AUTOSAR XML (schema 4-0-3)
standard types defined: Boolean, UInt8
package /AUTOSAR_Platform/DataConstrs
  range DC_Boolean: raw 0..1
package /PATAC/Facility/DataTypes/Implementation
  compu method COMPU_Boolean: 0=FALSE, 1=TRUE
  unit NoUnit: factor-si-to-unit=1, offset-si-to-unit=0
package /PATAC/MSM/ComponentTypes
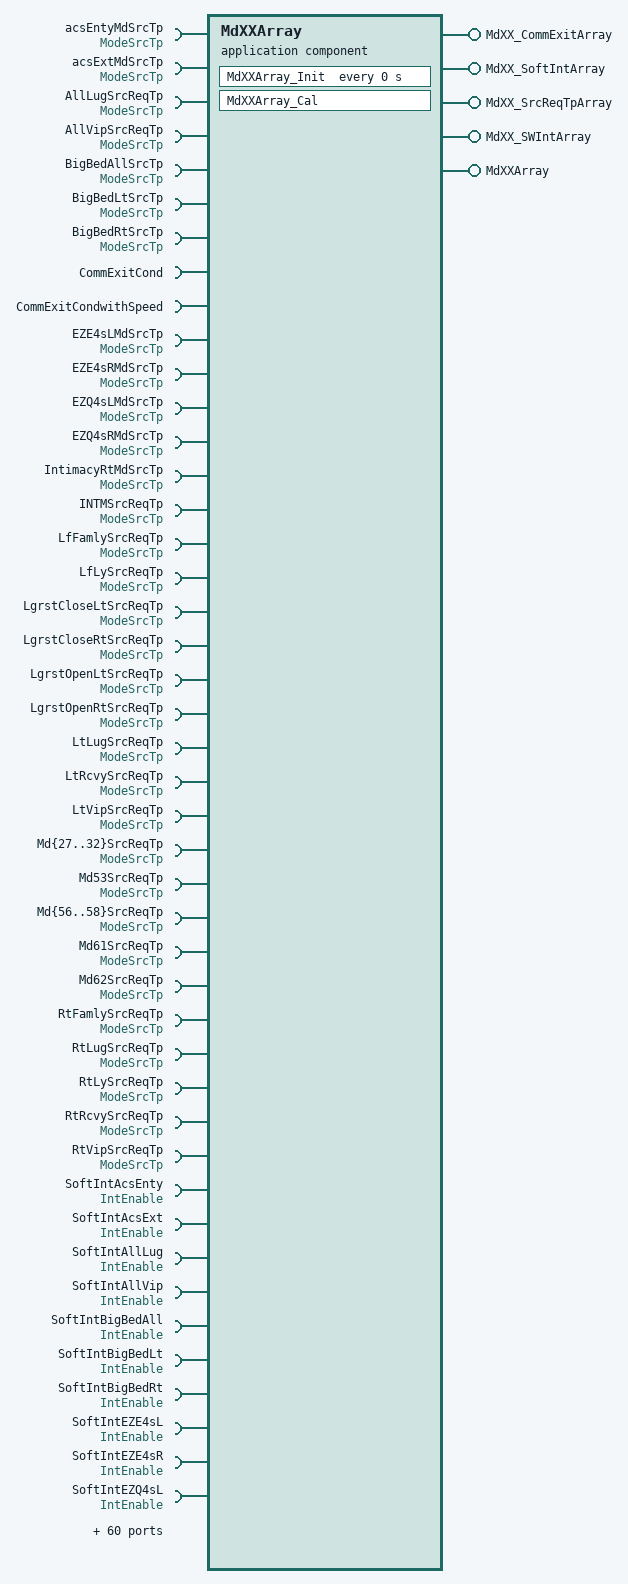
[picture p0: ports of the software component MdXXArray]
  application sw component type MdXXArray
    5 x provide port:
      MdXX_CommExitArray: nonqueued-sender-com-spec=data-element=MdXX_CommExitArray/Val, provided-interface=MdXX_CommExitArray
      MdXX_SoftIntArray: nonqueued-sender-com-spec{data-element=MdXX_SoftIntArray/Val, init-value=32 x 0}, provided-interface=MdXX_SoftIntArray
      MdXX_SrcReqTpArray: nonqueued-sender-com-spec{data-element=MdXX_SrcReqTpArray/Val, init-value=32 x 0}, provided-interface=MdXX_SrcReqTpArray
      MdXX_SWIntArray: nonqueued-sender-com-spec{data-element=MdXX_SWIntArray/Val, init-value=32 x 0}, provided-interface=MdXX_SWIntArray
      MdXXArray: server-com-spec{operation=Cal, queue-length=1}, provided-interface=MdXXArray
    125 x require port:
      acsEntyMdSrcTp: nonqueued-receiver-com-spec{data-element=ModeSrcTp/Val, filter=data-filter-type=ALWAYS, init-value=0}, required-interface=ModeSrcTp
      acsExtMdSrcTp: nonqueued-receiver-com-spec{data-element=ModeSrcTp/Val, filter=data-filter-type=ALWAYS, init-value=0}, required-interface=ModeSrcTp
      AllLugSrcReqTp: nonqueued-receiver-com-spec{data-element=ModeSrcTp/Val, filter=data-filter-type=ALWAYS, init-value=0}, required-interface=ModeSrcTp
      AllVipSrcReqTp: nonqueued-receiver-com-spec{data-element=ModeSrcTp/Val, filter=data-filter-type=ALWAYS, init-value=0}, required-interface=ModeSrcTp
      BigBedAllSrcTp: nonqueued-receiver-com-spec{data-element=ModeSrcTp/Val, filter=data-filter-type=ALWAYS, init-value=0}, required-interface=ModeSrcTp
      BigBedLtSrcTp: nonqueued-receiver-com-spec{data-element=ModeSrcTp/Val, filter=data-filter-type=ALWAYS, init-value=0}, required-interface=ModeSrcTp
      BigBedRtSrcTp: nonqueued-receiver-com-spec{data-element=ModeSrcTp/Val, filter=data-filter-type=ALWAYS, init-value=0}, required-interface=ModeSrcTp
      CommExitCond: nonqueued-receiver-com-spec{data-element=CommExitCond/Val, filter=data-filter-type=ALWAYS, init-value=0}, required-interface=CommExitCond
      CommExitCondwithSpeed: nonqueued-receiver-com-spec{data-element=CommExitCondwithSpeed/Val, filter=data-filter-type=ALWAYS, init-value=0}, required-interface=CommExitCondwithSpeed
      EZE4sLMdSrcTp: nonqueued-receiver-com-spec{data-element=ModeSrcTp/Val, filter=data-filter-type=ALWAYS, init-value=0}, required-interface=ModeSrcTp
      EZE4sRMdSrcTp: nonqueued-receiver-com-spec{data-element=ModeSrcTp/Val, filter=data-filter-type=ALWAYS, init-value=0}, required-interface=ModeSrcTp
      EZQ4sLMdSrcTp: nonqueued-receiver-com-spec{data-element=ModeSrcTp/Val, filter=data-filter-type=ALWAYS, init-value=0}, required-interface=ModeSrcTp
      EZQ4sRMdSrcTp: nonqueued-receiver-com-spec{data-element=ModeSrcTp/Val, filter=data-filter-type=ALWAYS, init-value=0}, required-interface=ModeSrcTp
      IntimacyRtMdSrcTp: nonqueued-receiver-com-spec{data-element=ModeSrcTp/Val, filter=data-filter-type=ALWAYS, init-value=0}, required-interface=ModeSrcTp
      INTMSrcReqTp: nonqueued-receiver-com-spec{data-element=ModeSrcTp/Val, filter=data-filter-type=ALWAYS, init-value=0}, required-interface=ModeSrcTp
      LfFamlySrcReqTp: nonqueued-receiver-com-spec{data-element=ModeSrcTp/Val, filter=data-filter-type=ALWAYS, init-value=0}, required-interface=ModeSrcTp
      LfLySrcReqTp: nonqueued-receiver-com-spec{data-element=ModeSrcTp/Val, filter=data-filter-type=ALWAYS, init-value=0}, required-interface=ModeSrcTp
      LgrstCloseLtSrcReqTp: nonqueued-receiver-com-spec{data-element=ModeSrcTp/Val, filter=data-filter-type=ALWAYS, init-value=0}, required-interface=ModeSrcTp
      LgrstCloseRtSrcReqTp: nonqueued-receiver-com-spec{data-element=ModeSrcTp/Val, filter=data-filter-type=ALWAYS, init-value=0}, required-interface=ModeSrcTp
      LgrstOpenLtSrcReqTp: nonqueued-receiver-com-spec{data-element=ModeSrcTp/Val, filter=data-filter-type=ALWAYS, init-value=0}, required-interface=ModeSrcTp
      LgrstOpenRtSrcReqTp: nonqueued-receiver-com-spec{data-element=ModeSrcTp/Val, filter=data-filter-type=ALWAYS, init-value=0}, required-interface=ModeSrcTp
      LtLugSrcReqTp: nonqueued-receiver-com-spec{data-element=ModeSrcTp/Val, filter=data-filter-type=ALWAYS, init-value=0}, required-interface=ModeSrcTp
      LtRcvySrcReqTp: nonqueued-receiver-com-spec{data-element=ModeSrcTp/Val, filter=data-filter-type=ALWAYS, init-value=0}, required-interface=ModeSrcTp
      LtVipSrcReqTp: nonqueued-receiver-com-spec{data-element=ModeSrcTp/Val, filter=data-filter-type=ALWAYS, init-value=0}, required-interface=ModeSrcTp
      Md{27..32}SrcReqTp: nonqueued-receiver-com-spec{data-element=ModeSrcTp/Val, filter=data-filter-type=ALWAYS, init-value=0}, required-interface=ModeSrcTp
      Md53SrcReqTp: nonqueued-receiver-com-spec{data-element=ModeSrcTp/Val, filter=data-filter-type=ALWAYS, init-value=0}, required-interface=ModeSrcTp
      Md{56..58}SrcReqTp: nonqueued-receiver-com-spec{data-element=ModeSrcTp/Val, filter=data-filter-type=ALWAYS, init-value=0}, required-interface=ModeSrcTp
      Md61SrcReqTp: nonqueued-receiver-com-spec{data-element=ModeSrcTp/Val, filter=data-filter-type=ALWAYS, init-value=0}, required-interface=ModeSrcTp
      Md62SrcReqTp: nonqueued-receiver-com-spec{data-element=ModeSrcTp/Val, filter=data-filter-type=ALWAYS, init-value=0}, required-interface=ModeSrcTp
      RtFamlySrcReqTp: nonqueued-receiver-com-spec{data-element=ModeSrcTp/Val, filter=data-filter-type=ALWAYS, init-value=0}, required-interface=ModeSrcTp
      RtLugSrcReqTp: nonqueued-receiver-com-spec{data-element=ModeSrcTp/Val, filter=data-filter-type=ALWAYS, init-value=0}, required-interface=ModeSrcTp
      RtLySrcReqTp: nonqueued-receiver-com-spec{data-element=ModeSrcTp/Val, filter=data-filter-type=ALWAYS, init-value=0}, required-interface=ModeSrcTp
      RtRcvySrcReqTp: nonqueued-receiver-com-spec{data-element=ModeSrcTp/Val, filter=data-filter-type=ALWAYS, init-value=0}, required-interface=ModeSrcTp
      RtVipSrcReqTp: nonqueued-receiver-com-spec{data-element=ModeSrcTp/Val, filter=data-filter-type=ALWAYS, init-value=0}, required-interface=ModeSrcTp
      SoftIntAcsEnty: nonqueued-receiver-com-spec{data-element=IntEnable/Val, filter=data-filter-type=ALWAYS, init-value=0}, required-interface=IntEnable
      SoftIntAcsExt: nonqueued-receiver-com-spec{data-element=IntEnable/Val, filter=data-filter-type=ALWAYS, init-value=0}, required-interface=IntEnable
      SoftIntAllLug: nonqueued-receiver-com-spec{data-element=IntEnable/Val, filter=data-filter-type=ALWAYS, init-value=0}, required-interface=IntEnable
      SoftIntAllVip: nonqueued-receiver-com-spec{data-element=IntEnable/Val, filter=data-filter-type=ALWAYS, init-value=0}, required-interface=IntEnable
      SoftIntBigBedAll: nonqueued-receiver-com-spec{data-element=IntEnable/Val, filter=data-filter-type=ALWAYS, init-value=0}, required-interface=IntEnable
      SoftIntBigBedLt: nonqueued-receiver-com-spec{data-element=IntEnable/Val, filter=data-filter-type=ALWAYS, init-value=0}, required-interface=IntEnable
      SoftIntBigBedRt: nonqueued-receiver-com-spec{data-element=IntEnable/Val, filter=data-filter-type=ALWAYS, init-value=0}, required-interface=IntEnable
      SoftIntEZE4sL: nonqueued-receiver-com-spec{data-element=IntEnable/Val, filter=data-filter-type=ALWAYS, init-value=0}, required-interface=IntEnable
      SoftIntEZE4sR: nonqueued-receiver-com-spec{data-element=IntEnable/Val, filter=data-filter-type=ALWAYS, init-value=0}, required-interface=IntEnable
      SoftIntEZQ4sL: nonqueued-receiver-com-spec{data-element=IntEnable/Val, filter=data-filter-type=ALWAYS, init-value=0}, required-interface=IntEnable
      SoftIntEZQ4sR: nonqueued-receiver-com-spec{data-element=IntEnable/Val, filter=data-filter-type=ALWAYS, init-value=0}, required-interface=IntEnable
      SoftIntIntimacyRt: nonqueued-receiver-com-spec{data-element=IntEnable/Val, filter=data-filter-type=ALWAYS, init-value=0}, required-interface=IntEnable
      SoftIntINTM: nonqueued-receiver-com-spec{data-element=IntEnable/Val, filter=data-filter-type=ALWAYS, init-value=0}, required-interface=IntEnable
      SoftIntLfFamly: nonqueued-receiver-com-spec{data-element=IntEnable/Val, filter=data-filter-type=ALWAYS, init-value=0}, required-interface=IntEnable
      SoftIntLfLug: nonqueued-receiver-com-spec{data-element=IntEnable/Val, filter=data-filter-type=ALWAYS, init-value=0}, required-interface=IntEnable
      SoftIntLfLy: nonqueued-receiver-com-spec{data-element=IntEnable/Val, filter=data-filter-type=ALWAYS, init-value=0}, required-interface=IntEnable
      SoftIntLfRcvy: nonqueued-receiver-com-spec{data-element=IntEnable/Val, filter=data-filter-type=ALWAYS, init-value=0}, required-interface=IntEnable
      SoftIntLfVip: nonqueued-receiver-com-spec{data-element=IntEnable/Val, filter=data-filter-type=ALWAYS, init-value=0}, required-interface=IntEnable
      SoftIntLgrstCloseLt: nonqueued-receiver-com-spec{data-element=IntEnable/Val, filter=data-filter-type=ALWAYS, init-value=0}, required-interface=IntEnable
      SoftIntLgrstCloseRt: nonqueued-receiver-com-spec{data-element=IntEnable/Val, filter=data-filter-type=ALWAYS, init-value=0}, required-interface=IntEnable
      SoftIntLgrstOpenLt: nonqueued-receiver-com-spec{data-element=IntEnable/Val, filter=data-filter-type=ALWAYS, init-value=0}, required-interface=IntEnable
      SoftIntLgrstOpenRt: nonqueued-receiver-com-spec{data-element=IntEnable/Val, filter=data-filter-type=ALWAYS, init-value=0}, required-interface=IntEnable
      SoftIntMd{27..32}: nonqueued-receiver-com-spec{data-element=IntEnable/Val, filter=data-filter-type=ALWAYS, init-value=0}, required-interface=IntEnable
      SoftIntMd53: nonqueued-receiver-com-spec{data-element=IntEnable/Val, filter=data-filter-type=ALWAYS, init-value=0}, required-interface=IntEnable
      SoftIntMd{56..58}: nonqueued-receiver-com-spec{data-element=IntEnable/Val, filter=data-filter-type=ALWAYS, init-value=0}, required-interface=IntEnable
      SoftIntMd61: nonqueued-receiver-com-spec{data-element=IntEnable/Val, filter=data-filter-type=ALWAYS, init-value=0}, required-interface=IntEnable
      SoftIntMd62: nonqueued-receiver-com-spec{data-element=IntEnable/Val, filter=data-filter-type=ALWAYS, init-value=0}, required-interface=IntEnable
      SoftIntRtFamly: nonqueued-receiver-com-spec{data-element=IntEnable/Val, filter=data-filter-type=ALWAYS, init-value=0}, required-interface=IntEnable
      SoftIntRtLug: nonqueued-receiver-com-spec{data-element=IntEnable/Val, filter=data-filter-type=ALWAYS, init-value=0}, required-interface=IntEnable
      SoftIntRtLy: nonqueued-receiver-com-spec{data-element=IntEnable/Val, filter=data-filter-type=ALWAYS, init-value=0}, required-interface=IntEnable
      SoftIntRtRcvy: nonqueued-receiver-com-spec{data-element=IntEnable/Val, filter=data-filter-type=ALWAYS, init-value=0}, required-interface=IntEnable
      SoftIntRtVip: nonqueued-receiver-com-spec{data-element=IntEnable/Val, filter=data-filter-type=ALWAYS, init-value=0}, required-interface=IntEnable
      SoftIntWelcomeBkwd: nonqueued-receiver-com-spec{data-element=IntEnable/Val, filter=data-filter-type=ALWAYS, init-value=0}, required-interface=IntEnable
      SoftIntWelcomeFwd: nonqueued-receiver-com-spec{data-element=IntEnable/Val, filter=data-filter-type=ALWAYS, init-value=0}, required-interface=IntEnable
      SwIntAcsEnty: nonqueued-receiver-com-spec{data-element=IntEnable/Val, filter=data-filter-type=ALWAYS, init-value=0}, required-interface=IntEnable
      SwIntAcsExt: nonqueued-receiver-com-spec{data-element=IntEnable/Val, filter=data-filter-type=ALWAYS, init-value=0}, required-interface=IntEnable
      SwIntAllLug: nonqueued-receiver-com-spec{data-element=IntEnable/Val, filter=data-filter-type=ALWAYS, init-value=0}, required-interface=IntEnable
      SwIntAllVip: nonqueued-receiver-com-spec{data-element=IntEnable/Val, filter=data-filter-type=ALWAYS, init-value=0}, required-interface=IntEnable
      SwIntBigBedAll: nonqueued-receiver-com-spec{data-element=IntEnable/Val, filter=data-filter-type=ALWAYS, init-value=0}, required-interface=IntEnable
      SwIntBigBedLt: nonqueued-receiver-com-spec{data-element=IntEnable/Val, filter=data-filter-type=ALWAYS, init-value=0}, required-interface=IntEnable
      SwIntBigBedRt: nonqueued-receiver-com-spec{data-element=IntEnable/Val, filter=data-filter-type=ALWAYS, init-value=0}, required-interface=IntEnable
      SwIntEZE4sL: nonqueued-receiver-com-spec{data-element=IntEnable/Val, filter=data-filter-type=ALWAYS, init-value=0}, required-interface=IntEnable
      SwIntEZE4sR: nonqueued-receiver-com-spec{data-element=IntEnable/Val, filter=data-filter-type=ALWAYS, init-value=0}, required-interface=IntEnable
      SwIntEZQ4sL: nonqueued-receiver-com-spec{data-element=IntEnable/Val, filter=data-filter-type=ALWAYS, init-value=0}, required-interface=IntEnable
      SwIntEZQ4sR: nonqueued-receiver-com-spec{data-element=IntEnable/Val, filter=data-filter-type=ALWAYS, init-value=0}, required-interface=IntEnable
      SwIntIntimacyRt: nonqueued-receiver-com-spec{data-element=IntEnable/Val, filter=data-filter-type=ALWAYS, init-value=0}, required-interface=IntEnable
      SwIntINTM: nonqueued-receiver-com-spec{data-element=IntEnable/Val, filter=data-filter-type=ALWAYS, init-value=0}, required-interface=IntEnable
      SwIntLfFamly: nonqueued-receiver-com-spec{data-element=IntEnable/Val, filter=data-filter-type=ALWAYS, init-value=0}, required-interface=IntEnable
      SwIntLfLug: nonqueued-receiver-com-spec{data-element=IntEnable/Val, filter=data-filter-type=ALWAYS, init-value=0}, required-interface=IntEnable
      SwIntLfLy: nonqueued-receiver-com-spec{data-element=IntEnable/Val, filter=data-filter-type=ALWAYS, init-value=0}, required-interface=IntEnable
      SwIntLfRcvy: nonqueued-receiver-com-spec{data-element=IntEnable/Val, filter=data-filter-type=ALWAYS, init-value=0}, required-interface=IntEnable
      SwIntLfVip: nonqueued-receiver-com-spec{data-element=IntEnable/Val, filter=data-filter-type=ALWAYS, init-value=0}, required-interface=IntEnable
      SwIntLgrstCloseLt: nonqueued-receiver-com-spec{data-element=IntEnable/Val, filter=data-filter-type=ALWAYS, init-value=0}, required-interface=IntEnable
      SwIntLgrstCloseRt: nonqueued-receiver-com-spec{data-element=IntEnable/Val, filter=data-filter-type=ALWAYS, init-value=0}, required-interface=IntEnable
      SwIntLgrstOpenLt: nonqueued-receiver-com-spec{data-element=IntEnable/Val, filter=data-filter-type=ALWAYS, init-value=0}, required-interface=IntEnable
      SwIntLgrstOpenRt: nonqueued-receiver-com-spec{data-element=IntEnable/Val, filter=data-filter-type=ALWAYS, init-value=0}, required-interface=IntEnable
      SwIntMd{27..32}: nonqueued-receiver-com-spec{data-element=IntEnable/Val, filter=data-filter-type=ALWAYS, init-value=0}, required-interface=IntEnable
      SwIntMd53: nonqueued-receiver-com-spec{data-element=IntEnable/Val, filter=data-filter-type=ALWAYS, init-value=0}, required-interface=IntEnable
      SwIntMd{56..58}: nonqueued-receiver-com-spec{data-element=IntEnable/Val, filter=data-filter-type=ALWAYS, init-value=0}, required-interface=IntEnable
      SwIntMd61: nonqueued-receiver-com-spec{data-element=IntEnable/Val, filter=data-filter-type=ALWAYS, init-value=0}, required-interface=IntEnable
      SwIntMd62: nonqueued-receiver-com-spec{data-element=IntEnable/Val, filter=data-filter-type=ALWAYS, init-value=0}, required-interface=IntEnable
      SwIntRtFamly: nonqueued-receiver-com-spec{data-element=IntEnable/Val, filter=data-filter-type=ALWAYS, init-value=0}, required-interface=IntEnable
      SwIntRtLug: nonqueued-receiver-com-spec{data-element=IntEnable/Val, filter=data-filter-type=ALWAYS, init-value=0}, required-interface=IntEnable
      SwIntRtLy: nonqueued-receiver-com-spec{data-element=IntEnable/Val, filter=data-filter-type=ALWAYS, init-value=0}, required-interface=IntEnable
      SwIntRtRcvy: nonqueued-receiver-com-spec{data-element=IntEnable/Val, filter=data-filter-type=ALWAYS, init-value=0}, required-interface=IntEnable
      SwIntRtVip: nonqueued-receiver-com-spec{data-element=IntEnable/Val, filter=data-filter-type=ALWAYS, init-value=0}, required-interface=IntEnable
      SwIntWelcomeBkwd: nonqueued-receiver-com-spec{data-element=IntEnable/Val, filter=data-filter-type=ALWAYS, init-value=0}, required-interface=IntEnable
      SwIntWelcomeFwd: nonqueued-receiver-com-spec{data-element=IntEnable/Val, filter=data-filter-type=ALWAYS, init-value=0}, required-interface=IntEnable
      WelcomeBkwdMdSrcTp: nonqueued-receiver-com-spec{data-element=ModeSrcTp/Val, filter=data-filter-type=ALWAYS, init-value=0}, required-interface=ModeSrcTp
      WelcomeFwdMdSrcTp: nonqueued-receiver-com-spec{data-element=ModeSrcTp/Val, filter=data-filter-type=ALWAYS, init-value=0}, required-interface=ModeSrcTp
    behavior MdXXArray_InternalBehavior
      operation invoked event OIT_MdXXArray_Cal_MdXXArray_Cal: start-on-event=MdXXArray_Cal, operation=MdXXArray.Cal
      timing event MdXXArray_InitEvent: start-on-event=MdXXArray_Init, period=0
      runnable MdXXArray_Cal
        data-receive-point-by-arguments:
          125 x access:
            REC_acsEntyMdSrcTp_Val: accessed-variable=acsEntyMdSrcTp.Val
            REC_acsExtMdSrcTp_Val: accessed-variable=acsExtMdSrcTp.Val
            REC_AllLugSrcReqTp_Val: accessed-variable=AllLugSrcReqTp.Val
            REC_AllVipSrcReqTp_Val: accessed-variable=AllVipSrcReqTp.Val
            REC_BigBedAllSrcTp_Val: accessed-variable=BigBedAllSrcTp.Val
            REC_BigBedLtSrcTp_Val: accessed-variable=BigBedLtSrcTp.Val
            REC_BigBedRtSrcTp_Val: accessed-variable=BigBedRtSrcTp.Val
            REC_CommExitCond_Val: accessed-variable=CommExitCond.Val
            REC_CommExitCondwithSpeed_Val: accessed-variable=CommExitCondwithSpeed.Val
            REC_EZE4sLMdSrcTp_Val: accessed-variable=EZE4sLMdSrcTp.Val
            REC_EZE4sRMdSrcTp_Val: accessed-variable=EZE4sRMdSrcTp.Val
            REC_EZQ4sLMdSrcTp_Val: accessed-variable=EZQ4sLMdSrcTp.Val
            REC_EZQ4sRMdSrcTp_Val: accessed-variable=EZQ4sRMdSrcTp.Val
            REC_IntimacyRtMdSrcTp_Val: accessed-variable=IntimacyRtMdSrcTp.Val
            REC_INTMSrcReqTp_Val: accessed-variable=INTMSrcReqTp.Val
            REC_LfFamlySrcReqTp_Val: accessed-variable=LfFamlySrcReqTp.Val
            REC_LfLySrcReqTp_Val: accessed-variable=LfLySrcReqTp.Val
            REC_LgrstCloseLtSrcReqTp_Val: accessed-variable=LgrstCloseLtSrcReqTp.Val
            REC_LgrstCloseRtSrcReqTp_Val: accessed-variable=LgrstCloseRtSrcReqTp.Val
            REC_LgrstOpenLtSrcReqTp_Val: accessed-variable=LgrstOpenLtSrcReqTp.Val
            REC_LgrstOpenRtSrcReqTp_Val: accessed-variable=LgrstOpenRtSrcReqTp.Val
            REC_LtLugSrcReqTp_Val: accessed-variable=LtLugSrcReqTp.Val
            REC_LtRcvySrcReqTp_Val: accessed-variable=LtRcvySrcReqTp.Val
            REC_LtVipSrcReqTp_Val: accessed-variable=LtVipSrcReqTp.Val
            REC_Md{27..32}SrcReqTp_Val: accessed-variable=Md{27..32}SrcReqTp.Val
            REC_Md53SrcReqTp_Val: accessed-variable=Md53SrcReqTp.Val
            REC_Md{56..58}SrcReqTp_Val: accessed-variable=Md{56..58}SrcReqTp.Val
            REC_Md61SrcReqTp_Val: accessed-variable=Md61SrcReqTp.Val
            REC_Md62SrcReqTp_Val: accessed-variable=Md62SrcReqTp.Val
            REC_RtFamlySrcReqTp_Val: accessed-variable=RtFamlySrcReqTp.Val
            REC_RtLugSrcReqTp_Val: accessed-variable=RtLugSrcReqTp.Val
            REC_RtLySrcReqTp_Val: accessed-variable=RtLySrcReqTp.Val
            REC_RtRcvySrcReqTp_Val: accessed-variable=RtRcvySrcReqTp.Val
            REC_RtVipSrcReqTp_Val: accessed-variable=RtVipSrcReqTp.Val
            REC_SoftIntAcsEnty_Val: accessed-variable=SoftIntAcsEnty.Val
            REC_SoftIntAcsExt_Val: accessed-variable=SoftIntAcsExt.Val
            REC_SoftIntAllLug_Val: accessed-variable=SoftIntAllLug.Val
            REC_SoftIntAllVip_Val: accessed-variable=SoftIntAllVip.Val
            REC_SoftIntBigBedAll_Val: accessed-variable=SoftIntBigBedAll.Val
            REC_SoftIntBigBedLt_Val: accessed-variable=SoftIntBigBedLt.Val
            REC_SoftIntBigBedRt_Val: accessed-variable=SoftIntBigBedRt.Val
            REC_SoftIntEZE4sL_Val: accessed-variable=SoftIntEZE4sL.Val
            REC_SoftIntEZE4sR_Val: accessed-variable=SoftIntEZE4sR.Val
            REC_SoftIntEZQ4sL_Val: accessed-variable=SoftIntEZQ4sL.Val
            REC_SoftIntEZQ4sR_Val: accessed-variable=SoftIntEZQ4sR.Val
            REC_SoftIntIntimacyRt_Val: accessed-variable=SoftIntIntimacyRt.Val
            REC_SoftIntINTM_Val: accessed-variable=SoftIntINTM.Val
            REC_SoftIntLfFamly_Val: accessed-variable=SoftIntLfFamly.Val
            REC_SoftIntLfLug_Val: accessed-variable=SoftIntLfLug.Val
            REC_SoftIntLfLy_Val: accessed-variable=SoftIntLfLy.Val
            REC_SoftIntLfRcvy_Val: accessed-variable=SoftIntLfRcvy.Val
            REC_SoftIntLfVip_Val: accessed-variable=SoftIntLfVip.Val
            REC_SoftIntLgrstCloseLt_Val: accessed-variable=SoftIntLgrstCloseLt.Val
            REC_SoftIntLgrstCloseRt_Val: accessed-variable=SoftIntLgrstCloseRt.Val
            REC_SoftIntLgrstOpenLt_Val: accessed-variable=SoftIntLgrstOpenLt.Val
            REC_SoftIntLgrstOpenRt_Val: accessed-variable=SoftIntLgrstOpenRt.Val
            REC_SoftIntMd{27..32}_Val: accessed-variable=SoftIntMd{27..32}.Val
            REC_SoftIntMd53_Val: accessed-variable=SoftIntMd53.Val
            REC_SoftIntMd{56..58}_Val: accessed-variable=SoftIntMd{56..58}.Val
            REC_SoftIntMd61_Val: accessed-variable=SoftIntMd61.Val
            REC_SoftIntMd62_Val: accessed-variable=SoftIntMd62.Val
            REC_SoftIntRtFamly_Val: accessed-variable=SoftIntRtFamly.Val
            REC_SoftIntRtLug_Val: accessed-variable=SoftIntRtLug.Val
            REC_SoftIntRtLy_Val: accessed-variable=SoftIntRtLy.Val
            REC_SoftIntRtRcvy_Val: accessed-variable=SoftIntRtRcvy.Val
            REC_SoftIntRtVip_Val: accessed-variable=SoftIntRtVip.Val
            REC_SoftIntWelcomeBkwd_Val: accessed-variable=SoftIntWelcomeBkwd.Val
            REC_SoftIntWelcomeFwd_Val: accessed-variable=SoftIntWelcomeFwd.Val
            REC_SwIntAcsEnty_Val: accessed-variable=SwIntAcsEnty.Val
            REC_SwIntAcsExt_Val: accessed-variable=SwIntAcsExt.Val
            REC_SwIntAllLug_Val: accessed-variable=SwIntAllLug.Val
            REC_SwIntAllVip_Val: accessed-variable=SwIntAllVip.Val
            REC_SwIntBigBedAll_Val: accessed-variable=SwIntBigBedAll.Val
            REC_SwIntBigBedLt_Val: accessed-variable=SwIntBigBedLt.Val
            REC_SwIntBigBedRt_Val: accessed-variable=SwIntBigBedRt.Val
            REC_SwIntEZE4sL_Val: accessed-variable=SwIntEZE4sL.Val
            REC_SwIntEZE4sR_Val: accessed-variable=SwIntEZE4sR.Val
            REC_SwIntEZQ4sL_Val: accessed-variable=SwIntEZQ4sL.Val
            REC_SwIntEZQ4sR_Val: accessed-variable=SwIntEZQ4sR.Val
            REC_SwIntIntimacyRt_Val: accessed-variable=SwIntIntimacyRt.Val
            REC_SwIntINTM_Val: accessed-variable=SwIntINTM.Val
            REC_SwIntLfFamly_Val: accessed-variable=SwIntLfFamly.Val
            REC_SwIntLfLug_Val: accessed-variable=SwIntLfLug.Val
            REC_SwIntLfLy_Val: accessed-variable=SwIntLfLy.Val
            REC_SwIntLfRcvy_Val: accessed-variable=SwIntLfRcvy.Val
            REC_SwIntLfVip_Val: accessed-variable=SwIntLfVip.Val
            REC_SwIntLgrstCloseLt_Val: accessed-variable=SwIntLgrstCloseLt.Val
            REC_SwIntLgrstCloseRt_Val: accessed-variable=SwIntLgrstCloseRt.Val
            REC_SwIntLgrstOpenLt_Val: accessed-variable=SwIntLgrstOpenLt.Val
            REC_SwIntLgrstOpenRt_Val: accessed-variable=SwIntLgrstOpenRt.Val
            REC_SwIntMd{27..32}_Val: accessed-variable=SwIntMd{27..32}.Val
            REC_SwIntMd53_Val: accessed-variable=SwIntMd53.Val
            REC_SwIntMd{56..58}_Val: accessed-variable=SwIntMd{56..58}.Val
            REC_SwIntMd61_Val: accessed-variable=SwIntMd61.Val
            REC_SwIntMd62_Val: accessed-variable=SwIntMd62.Val
            REC_SwIntRtFamly_Val: accessed-variable=SwIntRtFamly.Val
            REC_SwIntRtLug_Val: accessed-variable=SwIntRtLug.Val
            REC_SwIntRtLy_Val: accessed-variable=SwIntRtLy.Val
            REC_SwIntRtRcvy_Val: accessed-variable=SwIntRtRcvy.Val
            REC_SwIntRtVip_Val: accessed-variable=SwIntRtVip.Val
            REC_SwIntWelcomeBkwd_Val: accessed-variable=SwIntWelcomeBkwd.Val
            REC_SwIntWelcomeFwd_Val: accessed-variable=SwIntWelcomeFwd.Val
            REC_WelcomeBkwdMdSrcTp_Val: accessed-variable=WelcomeBkwdMdSrcTp.Val
            REC_WelcomeFwdMdSrcTp_Val: accessed-variable=WelcomeFwdMdSrcTp.Val
        data-send-points:
          4 x access:
            SEND_MdXX_CommExitArray_Val: accessed-variable=MdXX_CommExitArray.Val
            SEND_MdXX_SoftIntArray_Val: accessed-variable=MdXX_SoftIntArray.Val
            SEND_MdXX_SrcReqTpArray_Val: accessed-variable=MdXX_SrcReqTpArray.Val
            SEND_MdXX_SWIntArray_Val: accessed-variable=MdXX_SWIntArray.Val
      runnable MdXXArray_Init
  swc implementation MdXXArray_Implementation: behavior=MdXXArray_InternalBehavior
    code-descriptors:
      code Default: artifact-descriptors=autosar-engineering-object={short-label=Default, category=SWSRC}
package /PATAC/MSM/DataTypes/ImplementationDataTypes
  impl type IntEnable: category=VALUE, base-type=Boolean, sw-calibration-access=READ-ONLY, type-emitter=RTE
package /PATAC/MSM/ModeAdjust/DataType
  impl type array1x32_Boolean: category=ARRAY, sw-calibration-access=READ-ONLY, type-emitter=RTE
    element Element: array-size=32, array-size-semantics=FIXED-SIZE, implementation-data-type=Boolean
  impl type array1x32_SrcReqTp: category=ARRAY, sw-calibration-access=READ-ONLY, type-emitter=RTE
    element Element: array-size=32, array-size-semantics=FIXED-SIZE, implementation-data-type=SrcReqTp1
  impl type SrcReqTp1: category=VALUE, base-type=UInt8, sw-calibration-access=READ-ONLY, compu {0=SrcReqTp_None, 1=SrcReqTp_Local, 2=SrcReqTp_HMI2L, 3=SrcReqTp_HMI2R, 4=SrcReqTp_HMI, 5=SrcReqTp_Remote, 6=SrcReqTp_SRS}, type-emitter=RTE
package /PATAC/MSM/ModeAdjust/PortInterface
  client server interface MdXXArray
    operation Cal
  8 x sender receiver interface:
    CommExitCond: invalidation-policy{data-element=CommExitCond/Val, handle-invalid=DONT-INVALIDATE}
      data Val: type=Boolean
    CommExitCondwithSpeed: invalidation-policy{data-element=CommExitCondwithSpeed/Val, handle-invalid=DONT-INVALIDATE}
      data Val: type=Boolean
    IntEnable: invalidation-policy{data-element=IntEnable/Val, handle-invalid=DONT-INVALIDATE}
      data Val: type=IntEnable
    MdXX_CommExitArray: invalidation-policy{data-element=MdXX_CommExitArray/Val, handle-invalid=DONT-INVALIDATE}
      data Val: type=array1x32_Boolean
    MdXX_SoftIntArray: invalidation-policy{data-element=MdXX_SoftIntArray/Val, handle-invalid=DONT-INVALIDATE}
      data Val: type=array1x32_Boolean
    MdXX_SrcReqTpArray: invalidation-policy{data-element=MdXX_SrcReqTpArray/Val, handle-invalid=DONT-INVALIDATE}
      data Val: type=array1x32_SrcReqTp
    MdXX_SWIntArray: invalidation-policy{data-element=MdXX_SWIntArray/Val, handle-invalid=DONT-INVALIDATE}
      data Val: type=array1x32_Boolean
    ModeSrcTp: invalidation-policy{data-element=ModeSrcTp/Val, handle-invalid=DONT-INVALIDATE}
      data Val: type=SrcReqTp1
